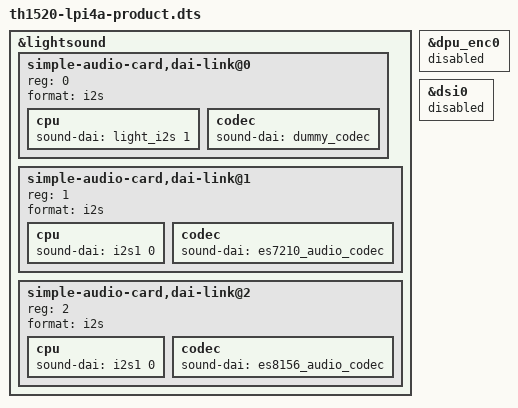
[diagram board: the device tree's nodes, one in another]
/* SPDX-License-Identifier: GPL-2.0 */	
/*
 * Copyright (C) 2021 Alibaba Group Holding Limited.
 */

/dts-v1/;

#include "th1520-lpi4a-dsi0.dts"

&lightsound {
        status = "okay";
        simple-audio-card,dai-link@0 {          /* I2S - HDMI*/
                reg = <0>;
                format = "i2s";
                cpu {
                        sound-dai = <&light_i2s 1>;
                };
                codec {
                        sound-dai = <&dummy_codec>;
                };
        };
        simple-audio-card,dai-link@1 {          /* I2S - AUDIO SYS CODEC 7210*/
                reg = <1>;
                format = "i2s";
                cpu {
                        sound-dai = <&i2s1 0>;
                };
                codec {
                        sound-dai = <&es7210_audio_codec>;
                };
        };
        simple-audio-card,dai-link@2 {          /* I2S - AUDIO SYS CODEC 8156*/
                reg = <2>;
                format = "i2s";
                cpu {
                        sound-dai = <&i2s1 0>;
                };
                codec {
                        sound-dai = <&es8156_audio_codec>;
                };
        };
};

&dpu_enc0 {
        status = "disabled";
};

&dsi0 {
        status = "disabled";
};
